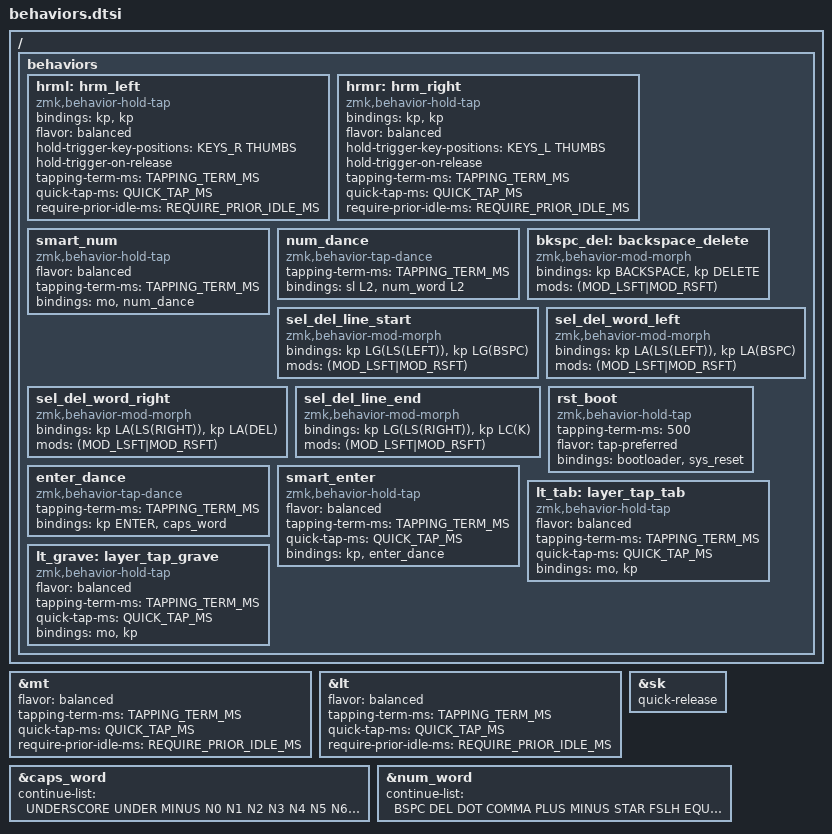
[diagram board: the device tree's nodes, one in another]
// ZMK Behaviors Configuration
&mt {
  flavor = "balanced";
  tapping-term-ms = <TAPPING_TERM_MS>;
  quick-tap-ms = <QUICK_TAP_MS>;
  require-prior-idle-ms = <REQUIRE_PRIOR_IDLE_MS>;
};

&lt {
  flavor = "balanced";
  tapping-term-ms = <TAPPING_TERM_MS>;
  quick-tap-ms = <QUICK_TAP_MS>;
  require-prior-idle-ms = <REQUIRE_PRIOR_IDLE_MS>;
};

&sk {
  quick-release;
};

// Customize caps_word for R/LaTeX workflow
// Allows: underscore (snake_case), numbers (var_123), minus (some R function names)
// LaTeX: curly braces for labels (\label{FIG_MAIN}), caret for superscripts
&caps_word {
  continue-list = <UNDERSCORE UNDER MINUS N0 N1 N2 N3 N4 N5 N6 N7 N8 N9 LBRC RBRC CARET BSPC DEL>;
};

// From: https://github.com/urob/zmk-config/
// num-word, requires PR https://github.com/zmkfirmware/zmk/pull/1451
// Adds arrows and shift to smart layer for more comfortable navigation/selection moves
&num_word {
  continue-list = <BSPC DEL DOT COMMA PLUS MINUS STAR FSLH EQUAL RSHFT LEFT RIGHT UP DOWN>;
};

/ {
  behaviors {
    /*
    Home Row Mods

    - tap: &kp <PARAM_2>
    - hold: &kp <PARAM_1>

    Example: &hrml LCMD T
    */
    /omit-if-no-ref/ hrml: hrm_left {
      bindings = <&kp>, <&kp>;
      compatible = "zmk,behavior-hold-tap";
      flavor = "balanced";
      hold-trigger-key-positions = <KEYS_R THUMBS>;
      hold-trigger-on-release;
      tapping-term-ms = <TAPPING_TERM_MS>;
      quick-tap-ms = <QUICK_TAP_MS>;
      require-prior-idle-ms = <REQUIRE_PRIOR_IDLE_MS>;
      #binding-cells = <2>;
    };

    /omit-if-no-ref/ hrmr: hrm_right {
      bindings = <&kp>, <&kp>;
      compatible = "zmk,behavior-hold-tap";
      flavor = "balanced";
      hold-trigger-key-positions = <KEYS_L THUMBS>;
      hold-trigger-on-release;
      tapping-term-ms = <TAPPING_TERM_MS>;
      quick-tap-ms = <QUICK_TAP_MS>;
      require-prior-idle-ms = <REQUIRE_PRIOR_IDLE_MS>;
      #binding-cells = <2>;
    };

    /*
    - tap: num-word
    - hold: &mo layer

    From: https://github.com/urob/zmk-config/
    */
    /omit-if-no-ref/ smart_num: smart_num {
      compatible = "zmk,behavior-hold-tap";
      flavor = "balanced";
      tapping-term-ms = <TAPPING_TERM_MS>;
      bindings = <&mo>, <&num_dance>;
      #binding-cells = <2>;
    };

    /*
    - tap: &sl L2
    - tap x 2: &num_word

    From: https://github.com/urob/zmk-config/
    */
    /omit-if-no-ref/ num_dance: num_dance {
      compatible = "zmk,behavior-tap-dance";
      tapping-term-ms = <TAPPING_TERM_MS>;
      bindings = <&sl L2>, <&num_word L2>;
      #binding-cells = <0>;
    };

    /*
    - tap: backspace
    - hold: repeat backspace
    - shift + tap: delete
    - shift + hold: repeat delete

    From: https://zmk.dev/docs/behaviors/mod-morph#advanced-configuration
    */
    /omit-if-no-ref/ bkspc_del: backspace_delete {
      compatible = "zmk,behavior-mod-morph";
      bindings = <&kp BACKSPACE>, <&kp DELETE>;
      mods = <(MOD_LSFT|MOD_RSFT)>;
      #binding-cells = <0>;
    };

    /*
    Select/Delete word and line behaviors
    - tap: select (with shift+arrow)
    - shift + tap: delete

    Mirrors navigation row below: line start, word left, word right, line end
    */
    /omit-if-no-ref/ sel_del_line_start: sel_del_line_start {
      compatible = "zmk,behavior-mod-morph";
      bindings = <&kp LG(LS(LEFT))>, <&kp LG(BSPC)>;
      mods = <(MOD_LSFT|MOD_RSFT)>;
      #binding-cells = <0>;
    };

    /omit-if-no-ref/ sel_del_word_left: sel_del_word_left {
      compatible = "zmk,behavior-mod-morph";
      bindings = <&kp LA(LS(LEFT))>, <&kp LA(BSPC)>;
      mods = <(MOD_LSFT|MOD_RSFT)>;
      #binding-cells = <0>;
    };

    /omit-if-no-ref/ sel_del_word_right: sel_del_word_right {
      compatible = "zmk,behavior-mod-morph";
      bindings = <&kp LA(LS(RIGHT))>, <&kp LA(DEL)>;
      mods = <(MOD_LSFT|MOD_RSFT)>;
      #binding-cells = <0>;
    };

    /omit-if-no-ref/ sel_del_line_end: sel_del_line_end {
      compatible = "zmk,behavior-mod-morph";
      bindings = <&kp LG(LS(RIGHT))>, <&kp LC(K)>;
      mods = <(MOD_LSFT|MOD_RSFT)>;
      #binding-cells = <0>;
    };

    /*
    - tap: reset keyboard
    - hold: enter bootloader mode
    */
    /omit-if-no-ref/ rst_boot: rst_boot {
        compatible = "zmk,behavior-hold-tap";
        #binding-cells = <2>;
        tapping-term-ms = <500>;
        flavor = "tap-preferred";
        bindings = <&bootloader>, <&sys_reset>;
    };

    /*
    - tap: &kp ENTER
    - tap x 2: &caps_word

    Used in smart_enter below
    */
    /omit-if-no-ref/ enter_dance: enter_dance {
      compatible = "zmk,behavior-tap-dance";
      tapping-term-ms = <TAPPING_TERM_MS>;
      bindings = <&kp ENTER>, <&caps_word>;
      #binding-cells = <0>;
    };

    /*
    - tap: enter
    - double-tap: caps_word
    - hold: shift

    Combines Enter functionality with smart shift behavior
    */
    /omit-if-no-ref/ smart_enter: smart_enter {
      compatible = "zmk,behavior-hold-tap";
      flavor = "balanced";
      tapping-term-ms = <TAPPING_TERM_MS>;
      quick-tap-ms = <QUICK_TAP_MS>;
      bindings = <&kp>, <&enter_dance>;
      #binding-cells = <2>;
    };

    /*
    - tap: TAB
    - hold: Fn layer

    Ergonomic thumb-based Fn layer access (left thumb)
    */
    /omit-if-no-ref/ lt_tab: layer_tap_tab {
      compatible = "zmk,behavior-hold-tap";
      flavor = "balanced";
      tapping-term-ms = <TAPPING_TERM_MS>;
      quick-tap-ms = <QUICK_TAP_MS>;
      bindings = <&mo>, <&kp>;
      #binding-cells = <2>;
    };

    /*
    - tap: GRAVE (backtick)
    - hold: Fn layer

    Ergonomic thumb-based Fn layer access (right thumb)
    */
    /omit-if-no-ref/ lt_grave: layer_tap_grave {
      compatible = "zmk,behavior-hold-tap";
      flavor = "balanced";
      tapping-term-ms = <TAPPING_TERM_MS>;
      quick-tap-ms = <QUICK_TAP_MS>;
      bindings = <&mo>, <&kp>;
      #binding-cells = <2>;
    };
  };
};
